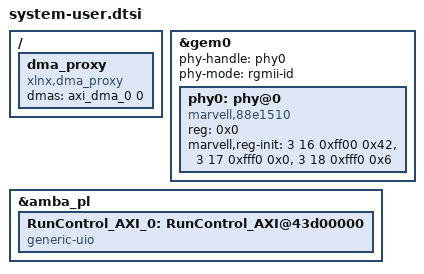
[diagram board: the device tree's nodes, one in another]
/include/ "system-conf.dtsi"

&gem0 {
	status = "okay";
    	phy-handle = <&phy0>;
      phy-mode = "rgmii-id";
    	phy0: phy@0 {
         compatible = "marvell,88e1510";
         device_type = "ethernet-phy";
         reg = <0x0>;
         /*
          * modify PHY registers to:
          * Reg 3_16
          * LED[1] bits [7:4] = ON=link, BLINK=activity, OFF=no activity
          * LED[0] bits [3:0] = link speed detect (3 blinks= 1Gbps, 2 blinks = 100Mbps, 1 blink = 10Mbps)
          * Reg 3_17
          * LED[1:0] = ON-drive low, OFF-high
          * Reg 3_18
          * LED[0] bits [3:2] = link speed LED blink off period = 170ms
          * LED[0] bits [1:0] = link speed LED blink on period = 340ms
          */
         marvell,reg-init = <3 16 0xff00 0x42>,
                  <3 17 0xfff0 0x0>,
                  <3 18 0xfff0 0x6>;
      };
};

/ {
   dma_proxy {
      compatible ="xlnx,dma_proxy";
      dmas = <&axi_dma_0 0>;
      dma-names = "dma_proxy_rx";
   };
};

&amba_pl {
   RunControl_AXI_0: RunControl_AXI@43d00000 {
      compatible = "generic-uio";
   };
};
